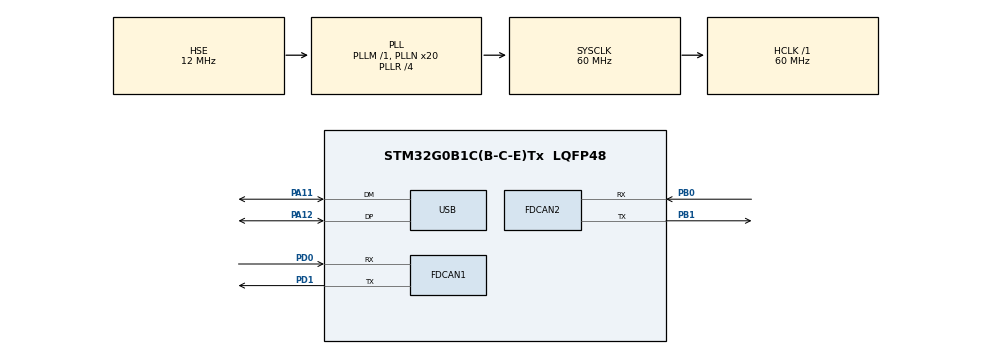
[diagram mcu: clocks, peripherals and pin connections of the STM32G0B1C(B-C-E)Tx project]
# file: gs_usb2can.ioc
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FDCAN1.CalculateBaudRateNominal=999999
FDCAN1.CalculateTimeBitNominal=1000
FDCAN1.CalculateTimeQuantumNominal=16.666666666666668
FDCAN1.DataSyncJumpWidth=3
FDCAN1.DataTimeSeg1=8
FDCAN1.DataTimeSeg2=3
FDCAN1.ExtFiltersNbr=1
FDCAN1.FrameFormat=FDCAN_FRAME_FD_NO_BRS
FDCAN1.NominalPrescaler=1
FDCAN1.NominalSyncJumpWidth=15
FDCAN1.NominalTimeSeg1=44
FDCAN1.NominalTimeSeg2=15
FDCAN1.StdFiltersNbr=1
FDCAN2.CalculateBaudRateNominal=999999
FDCAN2.CalculateTimeBitNominal=1000
FDCAN2.CalculateTimeQuantumNominal=16.666666666666668
FDCAN2.DataSyncJumpWidth=3
FDCAN2.DataTimeSeg1=8
FDCAN2.DataTimeSeg2=3
FDCAN2.ExtFiltersNbr=1
FDCAN2.FrameFormat=FDCAN_FRAME_FD_NO_BRS
FDCAN2.NominalPrescaler=1
FDCAN2.NominalSyncJumpWidth=15
FDCAN2.NominalTimeSeg1=44
FDCAN2.NominalTimeSeg2=15
FDCAN2.StdFiltersNbr=1
Mcu.Family=STM32G0
Mcu.Name=STM32G0B1C(B-C-E)Tx
Mcu.Package=LQFP48
NVIC.TIM16_FDCAN_IT0_IRQn=true\:0\:0\:false\:false\:true\:true\:true\:true
NVIC.TIM17_FDCAN_IT1_IRQn=true\:0\:0\:false\:false\:true\:true\:true\:true
NVIC.USB_UCPD1_2_IRQn=true\:2\:0\:true\:false\:true\:true\:true\:true
PA11\ [PA9].Mode=Device
PA11\ [PA9].Signal=USB_DM
PA12\ [PA10].Mode=Device
PA12\ [PA10].Signal=USB_DP
PA13.Mode=Serial_Wire
PA13.Signal=SYS_SWDIO
PA14-BOOT0.Mode=Serial_Wire
PA14-BOOT0.Signal=SYS_SWCLK
PB0.Mode=FDCAN_Activate
PB0.Signal=FDCAN2_RX
PB1.Mode=FDCAN_Activate
PB1.Signal=FDCAN2_TX
PD0.Mode=FDCAN_Activate
PD0.Signal=FDCAN1_RX
PD1.Mode=FDCAN_Activate
PD1.Signal=FDCAN1_TX
PF0-OSC_IN\ (PF0).Mode=HSE-External-Oscillator
PF0-OSC_IN\ (PF0).Signal=RCC_OSC_IN
PF1-OSC_OUT\ (PF1).Mode=HSE-External-Oscillator
PF1-OSC_OUT\ (PF1).Signal=RCC_OSC_OUT
ProjectManager.HeapSize=0x200
ProjectManager.StackSize=0x400
ProjectManager.TargetToolchain=CMake
RCC.ADCFreq_Value=60000000
RCC.AHBFreq_Value=60000000
RCC.CortexFreq_Value=60000000
RCC.EXTERNAL_CLOCK_VALUE=48000
RCC.HCLKFreq_Value=60000000
RCC.HSE_VALUE=12000000
RCC.HSI48_VALUE=48000000
RCC.HSI_VALUE=16000000
RCC.LSE_VALUE=32768
RCC.PLLN=20
RCC.PLLQ=RCC_PLLQ_DIV5
RCC.PLLR=RCC_PLLR_DIV4
RCC.PLLSourceVirtual=RCC_PLLSOURCE_HSE
RCC.SYSCLKFreq_VALUE=60000000
RCC.SYSCLKSource=RCC_SYSCLKSOURCE_PLLCLK
RCC.USBCLockSelection=RCC_USBCLKSOURCE_PLL
RCC.USBFreq_Value=48000000
RCC.VCOOutputFreq_Value=240000000
VP_SYS_VS_DBSignals.Mode=DisableDeadBatterySignals
board=custom

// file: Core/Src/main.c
/* USER CODE BEGIN Header */
/**
 ******************************************************************************
 * @file           : main.c
 * @brief          : Main program body
 ******************************************************************************
 * @attention
 *
 * Copyright (c) 2026 STMicroelectronics.
 * All rights reserved.
 *
 * This software is licensed under terms that can be found in the LICENSE file
 * in the root directory of this software component.
 * If no LICENSE file comes with this software, it is provided AS-IS.
 *
 ******************************************************************************
 */
/* USER CODE END Header */
#include "main.h"

#include "fdcan.h"
#include "gpio.h"
#include "usb_drd_fs.h"

void SystemClock_Config(void);

int main(void) {

    /* MCU Configuration--------------------------------------------------------*/

    /* Reset of all peripherals, Initializes the Flash interface and the Systick.
   */
    HAL_Init();

    /* Configure the system clock */
    SystemClock_Config();

    /* Initialize all configured peripherals */
    MX_GPIO_Init();
    MX_USB_DRD_FS_PCD_Init();
    MX_FDCAN1_Init();
    MX_FDCAN2_Init();
    /* USER CODE BEGIN 2 */
    HAL_PCD_EP_Open(&hpcd_USB_DRD_FS, 0x00, 64, EP_TYPE_CTRL);
    HAL_PCD_EP_Open(&hpcd_USB_DRD_FS, 0x80, 64, EP_TYPE_CTRL);
    HAL_PCD_Start(&hpcd_USB_DRD_FS);
    /* USER CODE END 2 */

    /* Infinite loop */
    while (1) {

    }
}

void SystemClock_Config(void) {
    RCC_OscInitTypeDef RCC_OscInitStruct = {0};
    RCC_ClkInitTypeDef RCC_ClkInitStruct = {0};

    /** Configure the main internal regulator output voltage
   */
    HAL_PWREx_ControlVoltageScaling(PWR_REGULATOR_VOLTAGE_SCALE1);

    /** Initializes the RCC Oscillators according to the specified parameters
   * in the RCC_OscInitTypeDef structure.
   */
    RCC_OscInitStruct.OscillatorType = RCC_OSCILLATORTYPE_HSE;
    RCC_OscInitStruct.HSEState = RCC_HSE_ON;
    RCC_OscInitStruct.PLL.PLLState = RCC_PLL_ON;
    RCC_OscInitStruct.PLL.PLLSource = RCC_PLLSOURCE_HSE;
    RCC_OscInitStruct.PLL.PLLM = RCC_PLLM_DIV1;
    RCC_OscInitStruct.PLL.PLLN = 20;
    RCC_OscInitStruct.PLL.PLLP = RCC_PLLP_DIV2;
    RCC_OscInitStruct.PLL.PLLQ = RCC_PLLQ_DIV5;
    RCC_OscInitStruct.PLL.PLLR = RCC_PLLR_DIV4;
    if (HAL_RCC_OscConfig(&RCC_OscInitStruct) != HAL_OK) { Error_Handler(); }

    /** Initializes the CPU, AHB and APB buses clocks
   */
    RCC_ClkInitStruct.ClockType = RCC_CLOCKTYPE_HCLK | RCC_CLOCKTYPE_SYSCLK | RCC_CLOCKTYPE_PCLK1;
    RCC_ClkInitStruct.SYSCLKSource = RCC_SYSCLKSOURCE_PLLCLK;
    RCC_ClkInitStruct.AHBCLKDivider = RCC_SYSCLK_DIV1;
    RCC_ClkInitStruct.APB1CLKDivider = RCC_HCLK_DIV1;

    if (HAL_RCC_ClockConfig(&RCC_ClkInitStruct, FLASH_LATENCY_2) != HAL_OK) { Error_Handler(); }
}

void Error_Handler(void) {
    __disable_irq();
    while (1) {}
}
#ifdef USE_FULL_ASSERT
/**
 * @brief  Reports the name of the source file and the source line number
 *         where the assert_param error has occurred.
 * @param  file: pointer to the source file name
 * @param  line: assert_param error line source number
 * @retval None
 */
void assert_failed(uint8_t *file, uint32_t line) {
    /* USER CODE BEGIN 6 */
    /* User can add his own implementation to report the file name and line
     number, ex: printf("Wrong parameters value: file %s on line %d\r\n", file,
     line) */
    /* USER CODE END 6 */
}
#endif /* USE_FULL_ASSERT */
